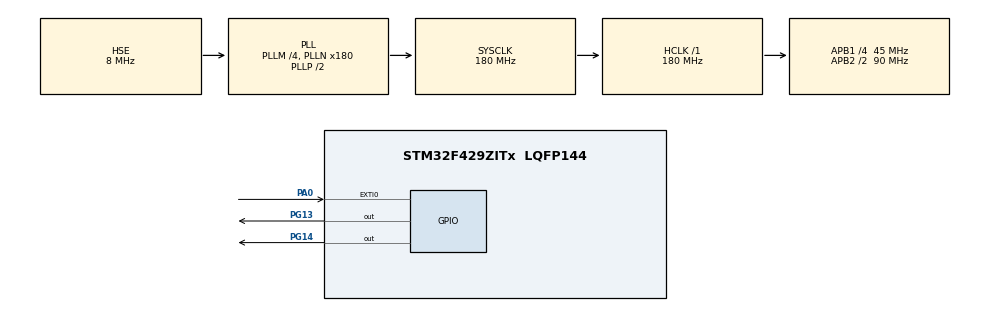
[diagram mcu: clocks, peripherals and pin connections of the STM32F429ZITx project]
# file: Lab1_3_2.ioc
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Mcu.Family=STM32F4
Mcu.Name=STM32F429ZITx
Mcu.Package=LQFP144
NVIC.EXTI0_IRQn=true\:0\:0\:false\:false\:true\:true\:true\:true
NVIC.PriorityGroup=NVIC_PRIORITYGROUP_4
NVIC.TIM6_DAC_IRQn=true\:0\:0\:false\:false\:true\:true\:true\:true
PA0/WKUP.Signal=GPXTI0
PG13.Signal=GPIO_Output
PG14.Signal=GPIO_Output
PH0/OSC_IN.Mode=HSE-External-Oscillator
PH0/OSC_IN.Signal=RCC_OSC_IN
PH1/OSC_OUT.Mode=HSE-External-Oscillator
PH1/OSC_OUT.Signal=RCC_OSC_OUT
ProjectManager.HeapSize=0x200
ProjectManager.StackSize=0x400
ProjectManager.TargetToolchain=STM32CubeIDE
RCC.48MHZClocksFreq_Value=90000000
RCC.AHBFreq_Value=180000000
RCC.APB1CLKDivider=RCC_HCLK_DIV4
RCC.APB1Freq_Value=45000000
RCC.APB1TimFreq_Value=90000000
RCC.APB2CLKDivider=RCC_HCLK_DIV2
RCC.APB2Freq_Value=90000000
RCC.APB2TimFreq_Value=180000000
RCC.CortexFreq_Value=180000000
RCC.HCLKFreq_Value=180000000
RCC.HSE_VALUE=8000000
RCC.HSI_VALUE=16000000
RCC.LSE_VALUE=32768
RCC.PLLM=4
RCC.PLLN=180
RCC.PLLSourceVirtual=RCC_PLLSOURCE_HSE
RCC.SYSCLKFreq_VALUE=180000000
RCC.SYSCLKSource=RCC_SYSCLKSOURCE_PLLCLK
RCC.VCOOutputFreq_Value=360000000
TIM6.Period=99
TIM6.Prescaler=89
VP_TIM6_VS_ClockSourceINT.Mode=Enable_Timer
board=custom

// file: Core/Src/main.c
/* USER CODE BEGIN Header */
/**
  ******************************************************************************
  * @file           : main.c
  * @brief          : Main program body
  ******************************************************************************
  * @attention
  *
  * Copyright (c) 2026 STMicroelectronics.
  * All rights reserved.
  *
  * This software is licensed under terms that can be found in the LICENSE file
  * in the root directory of this software component.
  * If no LICENSE file comes with this software, it is provided AS-IS.
  *
  ******************************************************************************
  */
/* USER CODE END Header */
#include "main.h"

TIM_HandleTypeDef htim6;

/* USER CODE BEGIN PV */
int TIM6_Count;
/* USER CODE END PV */

void SystemClock_Config(void);
static void MX_GPIO_Init(void);
static void MX_TIM6_Init(void);

/* USER CODE BEGIN 0 */
/* Three-segment wiring test: PE8-PE10 supply segments a/b/c on both digits. */
/* USER CODE END 0 */

int main(void)
{

  /* USER CODE BEGIN 1 */
  TIM6_Count = 0;
  /* USER CODE END 1 */

  /* MCU Configuration--------------------------------------------------------*/

  /* Reset of all peripherals, Initializes the Flash interface and the Systick. */
  HAL_Init();

  /* Configure the system clock */
  SystemClock_Config();

  /* Initialize all configured peripherals */
  MX_GPIO_Init();
  MX_TIM6_Init();
  /* USER CODE BEGIN 2 */
  HAL_TIM_Base_Start_IT(&htim6);
  /* USER CODE END 2 */

  /* Infinite loop */
  while (1)
  {

    /* USER CODE BEGIN 3 */
    HAL_GPIO_WritePin(GPIOG, GPIO_PIN_2 | GPIO_PIN_3, GPIO_PIN_RESET);
    HAL_GPIO_WritePin(GPIOE, GPIO_PIN_8 | GPIO_PIN_9 | GPIO_PIN_10, GPIO_PIN_SET);
    HAL_GPIO_WritePin(GPIOG, GPIO_PIN_2, GPIO_PIN_SET);
    HAL_Delay(500);
    HAL_GPIO_WritePin(GPIOG, GPIO_PIN_2, GPIO_PIN_RESET);
    HAL_GPIO_WritePin(GPIOG, GPIO_PIN_3, GPIO_PIN_SET);
    HAL_Delay(500);

  }
  /* USER CODE END 3 */
}

void SystemClock_Config(void)
{
  RCC_OscInitTypeDef RCC_OscInitStruct = {0};
  RCC_ClkInitTypeDef RCC_ClkInitStruct = {0};

  /** Configure the main internal regulator output voltage
  */
  __HAL_RCC_PWR_CLK_ENABLE();
  __HAL_PWR_VOLTAGESCALING_CONFIG(PWR_REGULATOR_VOLTAGE_SCALE1);

  /** Initializes the RCC Oscillators according to the specified parameters
  * in the RCC_OscInitTypeDef structure.
  */
  RCC_OscInitStruct.OscillatorType = RCC_OSCILLATORTYPE_HSE;
  RCC_OscInitStruct.HSEState = RCC_HSE_ON;
  RCC_OscInitStruct.PLL.PLLState = RCC_PLL_ON;
  RCC_OscInitStruct.PLL.PLLSource = RCC_PLLSOURCE_HSE;
  RCC_OscInitStruct.PLL.PLLM = 4;
  RCC_OscInitStruct.PLL.PLLN = 180;
  RCC_OscInitStruct.PLL.PLLP = RCC_PLLP_DIV2;
  RCC_OscInitStruct.PLL.PLLQ = 4;
  if (HAL_RCC_OscConfig(&RCC_OscInitStruct) != HAL_OK)
  {
    Error_Handler();
  }

  /** Activate the Over-Drive mode
  */
  if (HAL_PWREx_EnableOverDrive() != HAL_OK)
  {
    Error_Handler();
  }

  /** Initializes the CPU, AHB and APB buses clocks
  */
  RCC_ClkInitStruct.ClockType = RCC_CLOCKTYPE_HCLK|RCC_CLOCKTYPE_SYSCLK
                              |RCC_CLOCKTYPE_PCLK1|RCC_CLOCKTYPE_PCLK2;
  RCC_ClkInitStruct.SYSCLKSource = RCC_SYSCLKSOURCE_PLLCLK;
  RCC_ClkInitStruct.AHBCLKDivider = RCC_SYSCLK_DIV1;
  RCC_ClkInitStruct.APB1CLKDivider = RCC_HCLK_DIV4;
  RCC_ClkInitStruct.APB2CLKDivider = RCC_HCLK_DIV2;

  if (HAL_RCC_ClockConfig(&RCC_ClkInitStruct, FLASH_LATENCY_5) != HAL_OK)
  {
    Error_Handler();
  }
}

static void MX_TIM6_Init(void)
{

  TIM_MasterConfigTypeDef sMasterConfig = {0};

  htim6.Instance = TIM6;
  htim6.Init.Prescaler = 89;
  htim6.Init.CounterMode = TIM_COUNTERMODE_UP;
  htim6.Init.Period = 99;
  htim6.Init.AutoReloadPreload = TIM_AUTORELOAD_PRELOAD_DISABLE;
  if (HAL_TIM_Base_Init(&htim6) != HAL_OK)
  {
    Error_Handler();
  }
  sMasterConfig.MasterOutputTrigger = TIM_TRGO_RESET;
  sMasterConfig.MasterSlaveMode = TIM_MASTERSLAVEMODE_DISABLE;
  if (HAL_TIMEx_MasterConfigSynchronization(&htim6, &sMasterConfig) != HAL_OK)
  {
    Error_Handler();
  }

}

static void MX_GPIO_Init(void)
{
  GPIO_InitTypeDef GPIO_InitStruct = {0};

  /* GPIO Ports Clock Enable */
  __HAL_RCC_GPIOH_CLK_ENABLE();
  __HAL_RCC_GPIOA_CLK_ENABLE();
  __HAL_RCC_GPIOG_CLK_ENABLE();

  /*Configure GPIO pin Output Level */
  HAL_GPIO_WritePin(GPIOG, GPIO_PIN_13|GPIO_PIN_14, GPIO_PIN_RESET);

  /*Configure GPIO pin : PA0 */
  GPIO_InitStruct.Pin = GPIO_PIN_0;
  GPIO_InitStruct.Mode = GPIO_MODE_IT_RISING;
  GPIO_InitStruct.Pull = GPIO_NOPULL;
  HAL_GPIO_Init(GPIOA, &GPIO_InitStruct);

  /*Configure GPIO pins : PG13 PG14 */
  GPIO_InitStruct.Pin = GPIO_PIN_13|GPIO_PIN_14;
  GPIO_InitStruct.Mode = GPIO_MODE_OUTPUT_PP;
  GPIO_InitStruct.Pull = GPIO_NOPULL;
  GPIO_InitStruct.Speed = GPIO_SPEED_FREQ_LOW;
  HAL_GPIO_Init(GPIOG, &GPIO_InitStruct);

  /* EXTI interrupt init*/
  HAL_NVIC_SetPriority(EXTI0_IRQn, 0, 0);
  HAL_NVIC_EnableIRQ(EXTI0_IRQn);

  /* USER CODE BEGIN MX_GPIO_Init_2 */
  __HAL_RCC_GPIOE_CLK_ENABLE();
  HAL_GPIO_WritePin(GPIOE, 0xFF00U, GPIO_PIN_RESET);
  GPIO_InitStruct.Pin = 0xFF00U;
  GPIO_InitStruct.Mode = GPIO_MODE_OUTPUT_PP;
  GPIO_InitStruct.Pull = GPIO_NOPULL;
  GPIO_InitStruct.Speed = GPIO_SPEED_FREQ_LOW;
  HAL_GPIO_Init(GPIOE, &GPIO_InitStruct);
  HAL_GPIO_WritePin(GPIOG, GPIO_PIN_2 | GPIO_PIN_3, GPIO_PIN_RESET);
  GPIO_InitStruct.Pin = GPIO_PIN_2 | GPIO_PIN_3;
  HAL_GPIO_Init(GPIOG, &GPIO_InitStruct);
  /* USER CODE END MX_GPIO_Init_2 */
}

void Error_Handler(void)
{
  __disable_irq();
  while (1)
  {
  }
}
